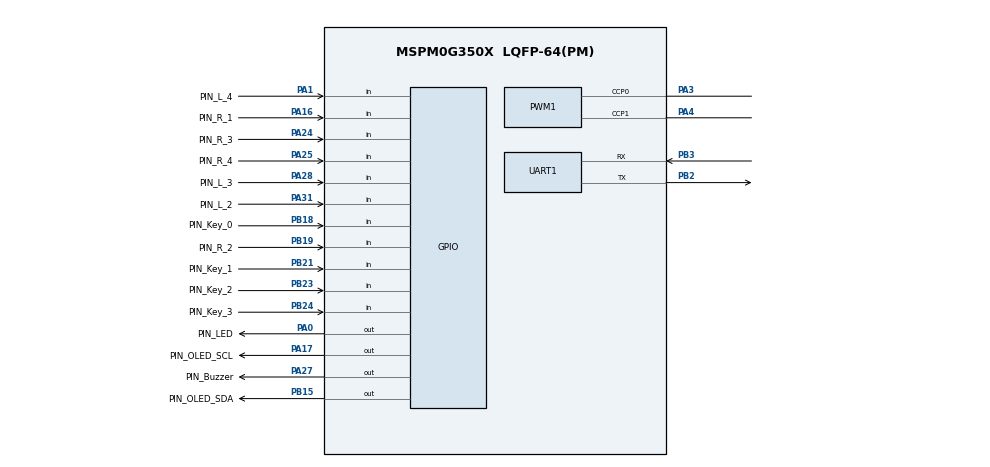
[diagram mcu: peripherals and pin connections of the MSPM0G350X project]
/**
 * @cliArgs --device "MSPM0G350X" --part "Default" --package "LQFP-64(PM)" --product "mspm0_sdk@2.10.00.04"
 * @versions {"tool":"1.26.2+4477"}
 */

/**
 * Import the modules used in this configuration.
 */
const GPIO    = scripting.addModule("/ti/driverlib/GPIO", {}, false);
const GPIO1   = GPIO.addInstance();
const GPIO2   = GPIO.addInstance();
const GPIO3   = GPIO.addInstance();
const GPIO4   = GPIO.addInstance();
const GPIO5   = GPIO.addInstance();
const GPIO6   = GPIO.addInstance();
const GPIO7   = GPIO.addInstance();
const PWM     = scripting.addModule("/ti/driverlib/PWM", {}, false);
const PWM1    = PWM.addInstance();
const SYSCTL  = scripting.addModule("/ti/driverlib/SYSCTL");
const SYSTICK = scripting.addModule("/ti/driverlib/SYSTICK");
const TIMER   = scripting.addModule("/ti/driverlib/TIMER", {}, false);
const TIMER1  = TIMER.addInstance();
const TIMER2  = TIMER.addInstance();
const TIMER3  = TIMER.addInstance();
const TIMER4  = TIMER.addInstance();
const UART    = scripting.addModule("/ti/driverlib/UART", {}, false);
const UART1   = UART.addInstance();
const UART2   = UART.addInstance();

/**
 * Write custom configuration values to the imported modules.
 */
const divider7       = system.clockTree["PLL_PDIV"];
divider7.divideValue = 2;

const divider9       = system.clockTree["UDIV"];
divider9.divideValue = 2;

const multiplier2         = system.clockTree["PLL_QDIV"];
multiplier2.multiplyValue = 5;

const mux8       = system.clockTree["HSCLKMUX"];
mux8.inputSelect = "HSCLKMUX_SYSPLL2X";

GPIO1.$name                         = "GPIO_OLED";
GPIO1.associatedPins.create(2);
GPIO1.associatedPins[0].$name       = "PIN_OLED_SCL";
GPIO1.associatedPins[0].pin.$assign = "PA17";
GPIO1.associatedPins[1].$name       = "PIN_OLED_SDA";
GPIO1.associatedPins[1].pin.$assign = "PB15";

const Board = scripting.addModule("/ti/driverlib/Board", {}, false);

GPIO2.$name                              = "GPIO_Motor";
GPIO2.port                               = "PORTB";
GPIO2.associatedPins.create(4);
GPIO2.associatedPins[0].$name            = "A_IN1";
GPIO2.associatedPins[0].internalResistor = "PULL_UP";
GPIO2.associatedPins[0].assignedPin      = "12";
GPIO2.associatedPins[1].$name            = "A_IN2";
GPIO2.associatedPins[1].assignedPin      = "9";
GPIO2.associatedPins[1].internalResistor = "PULL_UP";
GPIO2.associatedPins[2].$name            = "B_IN1";
GPIO2.associatedPins[2].assignedPin      = "10";
GPIO2.associatedPins[2].internalResistor = "PULL_UP";
GPIO2.associatedPins[3].$name            = "B_IN2";
GPIO2.associatedPins[3].assignedPin      = "11";
GPIO2.associatedPins[3].internalResistor = "PULL_UP";

GPIO3.port                               = "PORTB";
GPIO3.$name                              = "GPIO_Encoder";
GPIO3.associatedPins.create(4);
GPIO3.associatedPins[0].$name            = "Left_A";
GPIO3.associatedPins[0].direction        = "INPUT";
GPIO3.associatedPins[0].internalResistor = "PULL_DOWN";
GPIO3.associatedPins[0].interruptEn      = true;
GPIO3.associatedPins[0].polarity         = "RISE";
GPIO3.associatedPins[0].assignedPin      = "7";
GPIO3.associatedPins[1].$name            = "Left_B";
GPIO3.associatedPins[1].direction        = "INPUT";
GPIO3.associatedPins[1].internalResistor = "PULL_UP";
GPIO3.associatedPins[1].interruptEn      = true;
GPIO3.associatedPins[1].polarity         = "FALL";
GPIO3.associatedPins[1].assignedPin      = "6";
GPIO3.associatedPins[2].$name            = "Right_A";
GPIO3.associatedPins[2].direction        = "INPUT";
GPIO3.associatedPins[2].internalResistor = "PULL_DOWN";
GPIO3.associatedPins[2].polarity         = "RISE";
GPIO3.associatedPins[2].interruptEn      = true;
GPIO3.associatedPins[2].assignedPin      = "5";
GPIO3.associatedPins[3].$name            = "Right_B";
GPIO3.associatedPins[3].direction        = "INPUT";
GPIO3.associatedPins[3].internalResistor = "PULL_UP";
GPIO3.associatedPins[3].interruptEn      = true;
GPIO3.associatedPins[3].polarity         = "FALL";
GPIO3.associatedPins[3].assignedPin      = "4";

GPIO4.$name                         = "GPIO_Grayscale_Sensor";
GPIO4.associatedPins.create(8);
GPIO4.associatedPins[0].$name       = "PIN_L_4";
GPIO4.associatedPins[0].direction   = "INPUT";
GPIO4.associatedPins[0].pin.$assign = "PA1";
GPIO4.associatedPins[1].$name       = "PIN_L_3";
GPIO4.associatedPins[1].direction   = "INPUT";
GPIO4.associatedPins[1].pin.$assign = "PA28";
GPIO4.associatedPins[2].$name       = "PIN_L_2";
GPIO4.associatedPins[2].direction   = "INPUT";
GPIO4.associatedPins[2].pin.$assign = "PA31";
GPIO4.associatedPins[3].$name       = "PIN_L_1";
GPIO4.associatedPins[3].direction   = "INPUT";
GPIO4.associatedPins[4].$name       = "PIN_R_1";
GPIO4.associatedPins[4].direction   = "INPUT";
GPIO4.associatedPins[4].pin.$assign = "PA16";
GPIO4.associatedPins[5].$name       = "PIN_R_2";
GPIO4.associatedPins[5].direction   = "INPUT";
GPIO4.associatedPins[5].pin.$assign = "PB19";
GPIO4.associatedPins[6].$name       = "PIN_R_3";
GPIO4.associatedPins[6].direction   = "INPUT";
GPIO4.associatedPins[6].pin.$assign = "PA24";
GPIO4.associatedPins[7].$name       = "PIN_R_4";
GPIO4.associatedPins[7].direction   = "INPUT";
GPIO4.associatedPins[7].pin.$assign = "PA25";

GPIO5.$name                              = "GPIO_LED";
GPIO5.port                               = "PORTA";
GPIO5.associatedPins[0].$name            = "PIN_LED";
GPIO5.associatedPins[0].initialValue     = "SET";
GPIO5.associatedPins[0].internalResistor = "PULL_UP";
GPIO5.associatedPins[0].pin.$assign      = "PA0";

GPIO6.$name                              = "GPIO_Key";
GPIO6.associatedPins.create(4);
GPIO6.associatedPins[0].$name            = "PIN_Key_0";
GPIO6.associatedPins[0].direction        = "INPUT";
GPIO6.associatedPins[0].internalResistor = "PULL_UP";
GPIO6.associatedPins[0].pin.$assign      = "PB18";
GPIO6.associatedPins[1].$name            = "PIN_Key_1";
GPIO6.associatedPins[1].internalResistor = "PULL_UP";
GPIO6.associatedPins[1].direction        = "INPUT";
GPIO6.associatedPins[1].pin.$assign      = "PB21";
GPIO6.associatedPins[2].$name            = "PIN_Key_2";
GPIO6.associatedPins[2].direction        = "INPUT";
GPIO6.associatedPins[2].internalResistor = "PULL_UP";
GPIO6.associatedPins[2].pin.$assign      = "PB23";
GPIO6.associatedPins[3].$name            = "PIN_Key_3";
GPIO6.associatedPins[3].internalResistor = "PULL_UP";
GPIO6.associatedPins[3].direction        = "INPUT";
GPIO6.associatedPins[3].pin.$assign      = "PB24";

GPIO7.$name                              = "GPIO_Buzzer";
GPIO7.port                               = "PORTA";
GPIO7.associatedPins[0].internalResistor = "PULL_DOWN";
GPIO7.associatedPins[0].$name            = "PIN_Buzzer";
GPIO7.associatedPins[0].pin.$assign      = "PA27";

PWM1.$name                              = "PWM_MOTOR";
PWM1.clockDivider                       = 2;
PWM1.clockPrescale                      = 10;
PWM1.timerCount                         = 4000;
PWM1.peripheral.$assign                 = "TIMG7";
PWM1.peripheral.ccp0Pin.$assign         = "PA3";
PWM1.peripheral.ccp1Pin.$assign         = "PA4";
PWM1.PWM_CHANNEL_0.$name                = "ti_driverlib_pwm_PWMTimerCC0";
PWM1.PWM_CHANNEL_1.$name                = "ti_driverlib_pwm_PWMTimerCC1";
PWM1.ccp0PinConfig.$name                = "ti_driverlib_gpio_GPIOPinGeneric0";
PWM1.ccp0PinConfig.direction            = scripting.forceWrite("OUTPUT");
PWM1.ccp0PinConfig.hideOutputInversion  = scripting.forceWrite(false);
PWM1.ccp0PinConfig.onlyInternalResistor = scripting.forceWrite(false);
PWM1.ccp0PinConfig.passedPeripheralType = scripting.forceWrite("Digital");
PWM1.ccp1PinConfig.$name                = "ti_driverlib_gpio_GPIOPinGeneric1";
PWM1.ccp1PinConfig.direction            = scripting.forceWrite("OUTPUT");
PWM1.ccp1PinConfig.hideOutputInversion  = scripting.forceWrite(false);
PWM1.ccp1PinConfig.onlyInternalResistor = scripting.forceWrite(false);
PWM1.ccp1PinConfig.passedPeripheralType = scripting.forceWrite("Digital");

SYSCTL.forceDefaultClkConfig = true;
SYSCTL.clockTreeEn           = true;

SYSTICK.periodEnable    = true;
SYSTICK.period          = 80000;
SYSTICK.interruptEnable = true;
SYSTICK.systickEnable   = true;

TIMER1.timerClkPrescale   = 40;
TIMER1.interrupts         = ["ZERO"];
TIMER1.timerMode          = "PERIODIC";
TIMER1.$name              = "TIMER_Motor";
TIMER1.timerPeriod        = "1 ms";
TIMER1.peripheral.$assign = "TIMG0";

TIMER2.timerClkPrescale   = 40;
TIMER2.timerPeriod        = "10 ms";
TIMER2.timerMode          = "PERIODIC";
TIMER2.interrupts         = ["ZERO"];
TIMER2.$name              = "TIMER_Key";
TIMER2.peripheral.$assign = "TIMG8";

TIMER3.$name              = "TIMER_Grayscale_Sensor";
TIMER3.timerClkPrescale   = 80;
TIMER3.timerMode          = "PERIODIC";
TIMER3.interrupts         = ["ZERO"];
TIMER3.timerPeriod        = "10 ms";
TIMER3.peripheral.$assign = "TIMG6";

TIMER4.$name              = "TIMER_Speed";
TIMER4.timerPeriod        = "10 ms";
TIMER4.timerMode          = "PERIODIC";
TIMER4.interrupts         = ["ZERO"];
TIMER4.peripheral.$assign = "TIMG12";

UART1.$name                            = "UART_BlueSerial";
UART1.enabledInterrupts                = ["RX"];
UART1.peripheral.$assign               = "UART3";
UART1.peripheral.rxPin.$assign         = "PB3";
UART1.peripheral.txPin.$assign         = "PB2";
UART1.txPinConfig.$name                = "ti_driverlib_gpio_GPIOPinGeneric2";
UART1.txPinConfig.direction            = scripting.forceWrite("OUTPUT");
UART1.txPinConfig.hideOutputInversion  = scripting.forceWrite(false);
UART1.txPinConfig.onlyInternalResistor = scripting.forceWrite(false);
UART1.txPinConfig.passedPeripheralType = scripting.forceWrite("Digital");
UART1.rxPinConfig.$name                = "ti_driverlib_gpio_GPIOPinGeneric3";
UART1.rxPinConfig.hideOutputInversion  = scripting.forceWrite(false);
UART1.rxPinConfig.onlyInternalResistor = scripting.forceWrite(false);
UART1.rxPinConfig.passedPeripheralType = scripting.forceWrite("Digital");

UART2.$name                            = "UART_WIT";
UART2.targetBaudRate                   = 115200;
UART2.direction                        = "RX";
UART2.enableFIFO                       = true;
UART2.enabledInterrupts                = ["RX_TIMEOUT_ERROR"];
UART2.enabledDMARXTriggers             = "DL_UART_DMA_INTERRUPT_RX";
UART2.rxPinConfig.$name                = "ti_driverlib_gpio_GPIOPinGeneric5";
UART2.rxPinConfig.hideOutputInversion  = scripting.forceWrite(false);
UART2.rxPinConfig.onlyInternalResistor = scripting.forceWrite(false);
UART2.rxPinConfig.passedPeripheralType = scripting.forceWrite("Digital");
UART2.peripheral.$assign               = "UART2";
UART2.DMA_CHANNEL_RX.$name             = "DMA_WIT";
UART2.DMA_CHANNEL_RX.addressMode       = "f2b";
UART2.DMA_CHANNEL_RX.srcLength         = "BYTE";
UART2.DMA_CHANNEL_RX.dstLength         = "BYTE";

/**
 * Pinmux solution for unlocked pins/peripherals. This ensures that minor changes to the automatic solver in a future
 * version of the tool will not impact the pinmux you originally saw.  These lines can be completely deleted in order to
 * re-solve from scratch.
 */
Board.peripheral.$suggestSolution                = "DEBUGSS";
Board.peripheral.swclkPin.$suggestSolution       = "PA20";
Board.peripheral.swdioPin.$suggestSolution       = "PA19";
GPIO2.associatedPins[0].pin.$suggestSolution     = "PB12";
GPIO2.associatedPins[1].pin.$suggestSolution     = "PB9";
GPIO2.associatedPins[2].pin.$suggestSolution     = "PB10";
GPIO2.associatedPins[3].pin.$suggestSolution     = "PB11";
GPIO3.associatedPins[0].pin.$suggestSolution     = "PB7";
GPIO3.associatedPins[1].pin.$suggestSolution     = "PB6";
GPIO3.associatedPins[2].pin.$suggestSolution     = "PB5";
GPIO3.associatedPins[3].pin.$suggestSolution     = "PB4";
GPIO4.associatedPins[3].pin.$suggestSolution     = "PB13";
UART2.peripheral.rxPin.$suggestSolution          = "PA22";
UART2.DMA_CHANNEL_RX.peripheral.$suggestSolution = "DMA_CH0";
